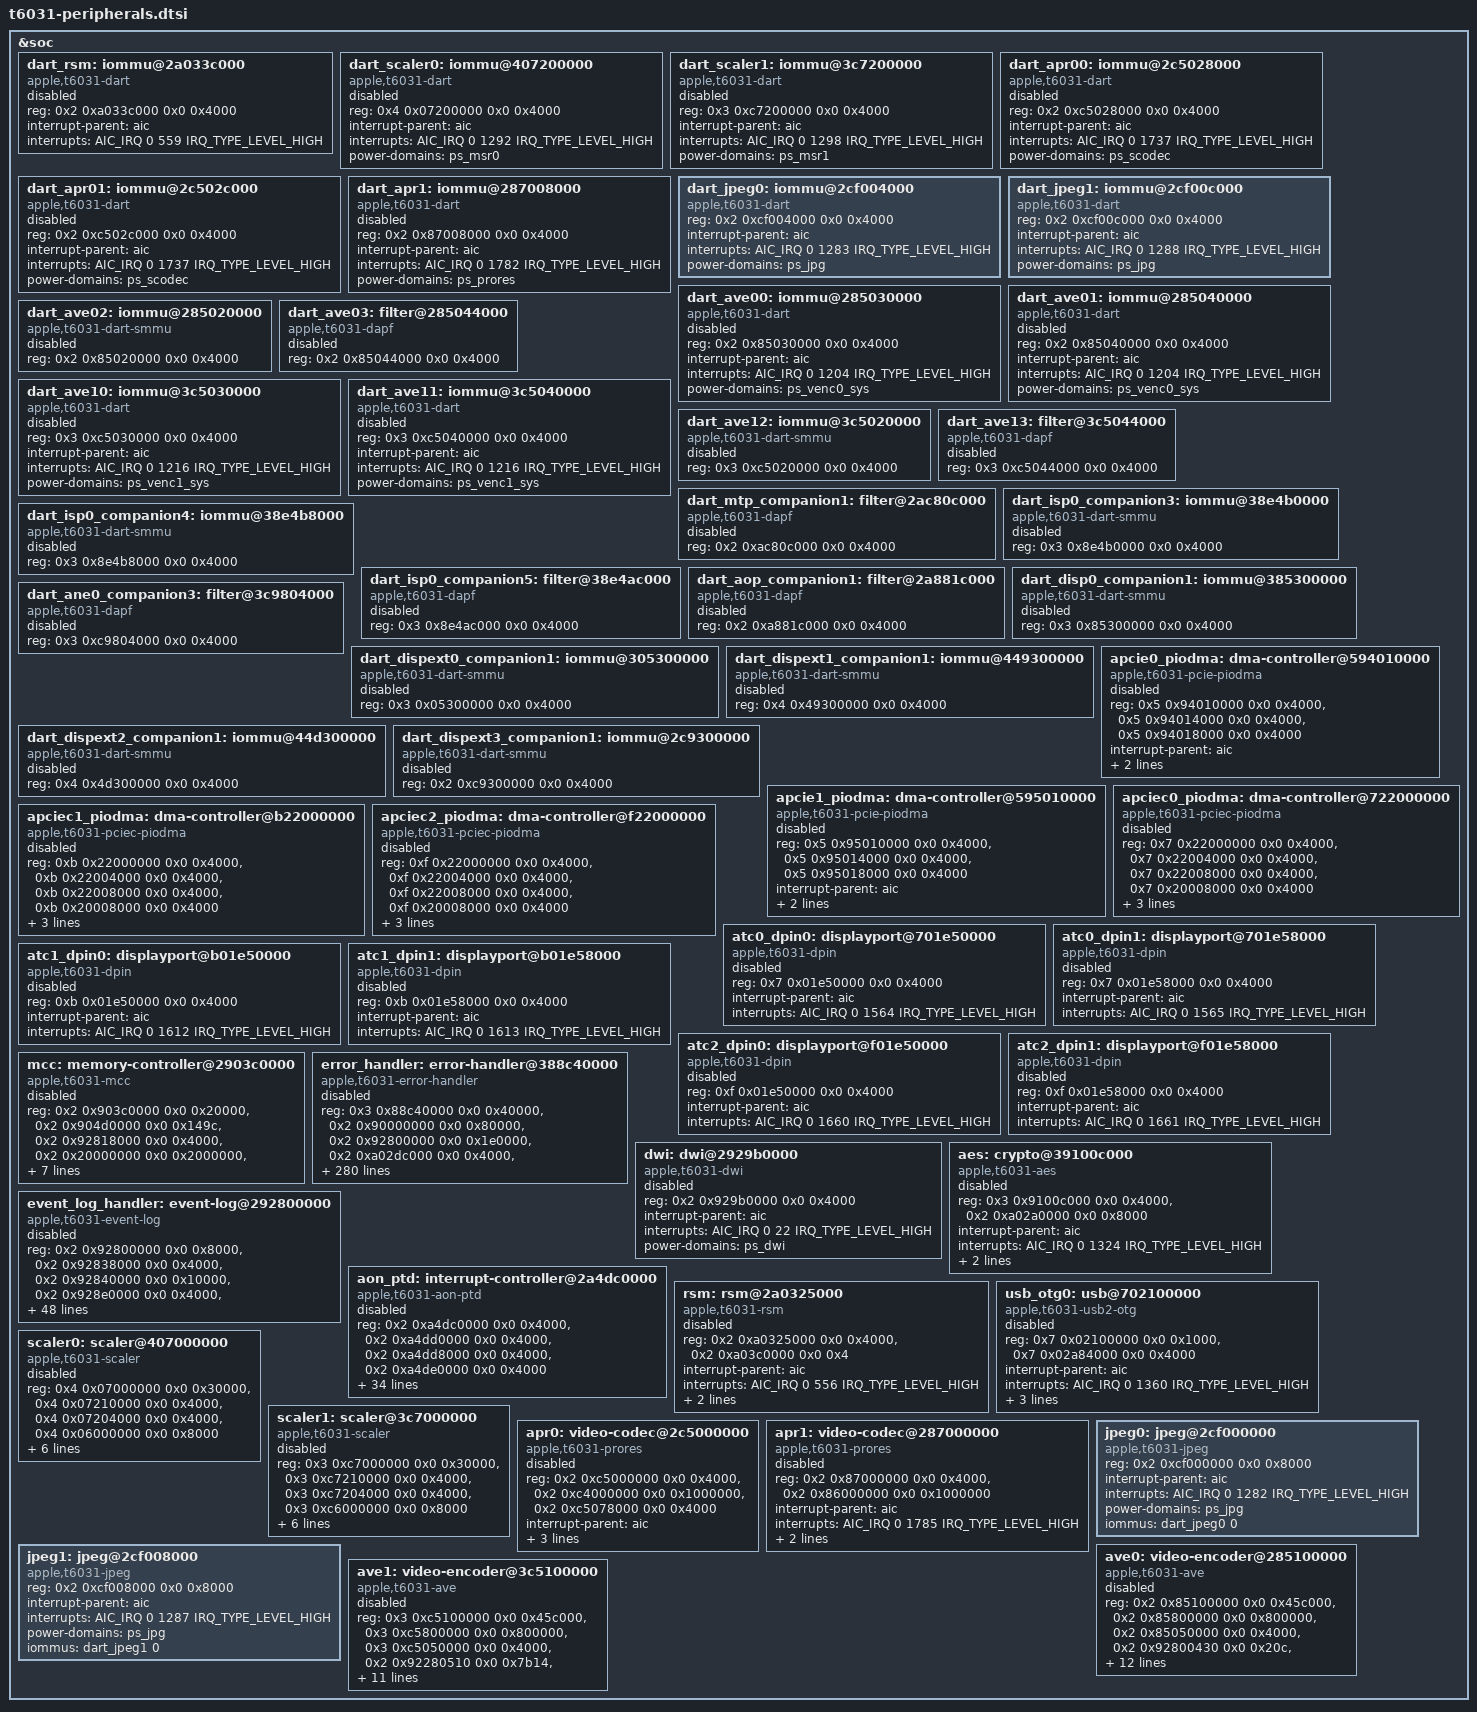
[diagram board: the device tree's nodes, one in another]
// SPDX-License-Identifier: GPL-2.0+ OR MIT
/* Additional T6031 hardware interfaces. Keep unclaimed engines disabled. */

&soc {
	dart_rsm: iommu@2a033c000 {
		compatible = "apple,t6031-dart", "apple,t8110-dart";
		reg = <0x2 0xa033c000 0x0 0x4000>;
		interrupt-parent = <&aic>;
		interrupts = <AIC_IRQ 0 559 IRQ_TYPE_LEVEL_HIGH>;
		#iommu-cells = <1>;
		status = "disabled";
	};

	dart_scaler0: iommu@407200000 {
		compatible = "apple,t6031-dart", "apple,t8110-dart";
		reg = <0x4 0x07200000 0x0 0x4000>;
		interrupt-parent = <&aic>;
		interrupts = <AIC_IRQ 0 1292 IRQ_TYPE_LEVEL_HIGH>;
		#iommu-cells = <1>;
		power-domains = <&ps_msr0>;
		status = "disabled";
	};

	dart_scaler1: iommu@3c7200000 {
		compatible = "apple,t6031-dart", "apple,t8110-dart";
		reg = <0x3 0xc7200000 0x0 0x4000>;
		interrupt-parent = <&aic>;
		interrupts = <AIC_IRQ 0 1298 IRQ_TYPE_LEVEL_HIGH>;
		#iommu-cells = <1>;
		power-domains = <&ps_msr1>;
		status = "disabled";
	};

	dart_apr00: iommu@2c5028000 {
		compatible = "apple,t6031-dart", "apple,t8110-dart";
		reg = <0x2 0xc5028000 0x0 0x4000>;
		interrupt-parent = <&aic>;
		interrupts = <AIC_IRQ 0 1737 IRQ_TYPE_LEVEL_HIGH>;
		#iommu-cells = <1>;
		power-domains = <&ps_scodec>;
		status = "disabled";
	};

	dart_apr01: iommu@2c502c000 {
		compatible = "apple,t6031-dart", "apple,t8110-dart";
		reg = <0x2 0xc502c000 0x0 0x4000>;
		interrupt-parent = <&aic>;
		interrupts = <AIC_IRQ 0 1737 IRQ_TYPE_LEVEL_HIGH>;
		#iommu-cells = <1>;
		power-domains = <&ps_scodec>;
		status = "disabled";
	};

	dart_apr1: iommu@287008000 {
		compatible = "apple,t6031-dart", "apple,t8110-dart";
		reg = <0x2 0x87008000 0x0 0x4000>;
		interrupt-parent = <&aic>;
		interrupts = <AIC_IRQ 0 1782 IRQ_TYPE_LEVEL_HIGH>;
		#iommu-cells = <1>;
		power-domains = <&ps_prores>;
		status = "disabled";
	};

	dart_jpeg0: iommu@2cf004000 {
		compatible = "apple,t6031-dart", "apple,t8110-dart";
		reg = <0x2 0xcf004000 0x0 0x4000>;
		interrupt-parent = <&aic>;
		interrupts = <AIC_IRQ 0 1283 IRQ_TYPE_LEVEL_HIGH>;
		#iommu-cells = <1>;
		power-domains = <&ps_jpg>;
		status = "okay";
	};

	dart_jpeg1: iommu@2cf00c000 {
		compatible = "apple,t6031-dart", "apple,t8110-dart";
		reg = <0x2 0xcf00c000 0x0 0x4000>;
		interrupt-parent = <&aic>;
		interrupts = <AIC_IRQ 0 1288 IRQ_TYPE_LEVEL_HIGH>;
		#iommu-cells = <1>;
		power-domains = <&ps_jpg>;
		status = "okay";
	};

	dart_ave00: iommu@285030000 {
		compatible = "apple,t6031-dart", "apple,t8110-dart";
		reg = <0x2 0x85030000 0x0 0x4000>;
		interrupt-parent = <&aic>;
		interrupts = <AIC_IRQ 0 1204 IRQ_TYPE_LEVEL_HIGH>;
		#iommu-cells = <1>;
		power-domains = <&ps_venc0_sys>;
		status = "disabled";
	};

	dart_ave01: iommu@285040000 {
		compatible = "apple,t6031-dart", "apple,t8110-dart";
		reg = <0x2 0x85040000 0x0 0x4000>;
		interrupt-parent = <&aic>;
		interrupts = <AIC_IRQ 0 1204 IRQ_TYPE_LEVEL_HIGH>;
		#iommu-cells = <1>;
		power-domains = <&ps_venc0_sys>;
		status = "disabled";
	};

	dart_ave02: iommu@285020000 {
		compatible = "apple,t6031-dart-smmu", "apple,dart-smmu";
		reg = <0x2 0x85020000 0x0 0x4000>;
		status = "disabled";
	};

	dart_ave03: filter@285044000 {
		compatible = "apple,t6031-dapf", "apple,dapf";
		reg = <0x2 0x85044000 0x0 0x4000>;
		status = "disabled";
	};

	dart_ave10: iommu@3c5030000 {
		compatible = "apple,t6031-dart", "apple,t8110-dart";
		reg = <0x3 0xc5030000 0x0 0x4000>;
		interrupt-parent = <&aic>;
		interrupts = <AIC_IRQ 0 1216 IRQ_TYPE_LEVEL_HIGH>;
		#iommu-cells = <1>;
		power-domains = <&ps_venc1_sys>;
		status = "disabled";
	};

	dart_ave11: iommu@3c5040000 {
		compatible = "apple,t6031-dart", "apple,t8110-dart";
		reg = <0x3 0xc5040000 0x0 0x4000>;
		interrupt-parent = <&aic>;
		interrupts = <AIC_IRQ 0 1216 IRQ_TYPE_LEVEL_HIGH>;
		#iommu-cells = <1>;
		power-domains = <&ps_venc1_sys>;
		status = "disabled";
	};

	dart_ave12: iommu@3c5020000 {
		compatible = "apple,t6031-dart-smmu", "apple,dart-smmu";
		reg = <0x3 0xc5020000 0x0 0x4000>;
		status = "disabled";
	};

	dart_ave13: filter@3c5044000 {
		compatible = "apple,t6031-dapf", "apple,dapf";
		reg = <0x3 0xc5044000 0x0 0x4000>;
		status = "disabled";
	};

	dart_mtp_companion1: filter@2ac80c000 {
		compatible = "apple,t6031-dapf", "apple,dapf";
		reg = <0x2 0xac80c000 0x0 0x4000>;
		status = "disabled";
	};

	dart_isp0_companion3: iommu@38e4b0000 {
		compatible = "apple,t6031-dart-smmu", "apple,dart-smmu";
		reg = <0x3 0x8e4b0000 0x0 0x4000>;
		status = "disabled";
	};

	dart_isp0_companion4: iommu@38e4b8000 {
		compatible = "apple,t6031-dart-smmu", "apple,dart-smmu";
		reg = <0x3 0x8e4b8000 0x0 0x4000>;
		status = "disabled";
	};

	dart_isp0_companion5: filter@38e4ac000 {
		compatible = "apple,t6031-dapf", "apple,dapf";
		reg = <0x3 0x8e4ac000 0x0 0x4000>;
		status = "disabled";
	};

	dart_aop_companion1: filter@2a881c000 {
		compatible = "apple,t6031-dapf", "apple,dapf";
		reg = <0x2 0xa881c000 0x0 0x4000>;
		status = "disabled";
	};

	dart_disp0_companion1: iommu@385300000 {
		compatible = "apple,t6031-dart-smmu", "apple,dart-smmu";
		reg = <0x3 0x85300000 0x0 0x4000>;
		status = "disabled";
	};

	dart_ane0_companion3: filter@3c9804000 {
		compatible = "apple,t6031-dapf", "apple,dapf";
		reg = <0x3 0xc9804000 0x0 0x4000>;
		status = "disabled";
	};

	dart_dispext0_companion1: iommu@305300000 {
		compatible = "apple,t6031-dart-smmu", "apple,dart-smmu";
		reg = <0x3 0x05300000 0x0 0x4000>;
		status = "disabled";
	};

	dart_dispext1_companion1: iommu@449300000 {
		compatible = "apple,t6031-dart-smmu", "apple,dart-smmu";
		reg = <0x4 0x49300000 0x0 0x4000>;
		status = "disabled";
	};

	dart_dispext2_companion1: iommu@44d300000 {
		compatible = "apple,t6031-dart-smmu", "apple,dart-smmu";
		reg = <0x4 0x4d300000 0x0 0x4000>;
		status = "disabled";
	};

	dart_dispext3_companion1: iommu@2c9300000 {
		compatible = "apple,t6031-dart-smmu", "apple,dart-smmu";
		reg = <0x2 0xc9300000 0x0 0x4000>;
		status = "disabled";
	};

	apcie0_piodma: dma-controller@594010000 {
		compatible = "apple,t6031-pcie-piodma", "apple,pcie-piodma";
		reg = <0x5 0x94010000 0x0 0x4000>,
		      <0x5 0x94014000 0x0 0x4000>,
		      <0x5 0x94018000 0x0 0x4000>;
		interrupt-parent = <&aic>;
		interrupts = <AIC_IRQ 0 1493 IRQ_TYPE_LEVEL_HIGH>;
		iommus = <&pcie0_dart_0 15>;
		status = "disabled";
	};

	apcie1_piodma: dma-controller@595010000 {
		compatible = "apple,t6031-pcie-piodma", "apple,pcie-piodma";
		reg = <0x5 0x95010000 0x0 0x4000>,
		      <0x5 0x95014000 0x0 0x4000>,
		      <0x5 0x95018000 0x0 0x4000>;
		interrupt-parent = <&aic>;
		interrupts = <AIC_IRQ 0 1502 IRQ_TYPE_LEVEL_HIGH>;
		iommus = <&pcie0_dart_1 15>;
		status = "disabled";
	};

	apciec0_piodma: dma-controller@722000000 {
		compatible = "apple,t6031-pciec-piodma", "apple,pciec-piodma";
		reg = <0x7 0x22000000 0x0 0x4000>,
		      <0x7 0x22004000 0x0 0x4000>,
		      <0x7 0x22008000 0x0 0x4000>,
		      <0x7 0x20008000 0x0 0x4000>;
		interrupt-parent = <&aic>;
		interrupts = <AIC_IRQ 0 1349 IRQ_TYPE_LEVEL_HIGH>;
		iommus = <&pciec0_dart 15>;
		status = "disabled";
	};

	apciec1_piodma: dma-controller@b22000000 {
		compatible = "apple,t6031-pciec-piodma", "apple,pciec-piodma";
		reg = <0xb 0x22000000 0x0 0x4000>,
		      <0xb 0x22004000 0x0 0x4000>,
		      <0xb 0x22008000 0x0 0x4000>,
		      <0xb 0x20008000 0x0 0x4000>;
		interrupt-parent = <&aic>;
		interrupts = <AIC_IRQ 0 1377 IRQ_TYPE_LEVEL_HIGH>;
		iommus = <&pciec1_dart 15>;
		status = "disabled";
	};

	apciec2_piodma: dma-controller@f22000000 {
		compatible = "apple,t6031-pciec-piodma", "apple,pciec-piodma";
		reg = <0xf 0x22000000 0x0 0x4000>,
		      <0xf 0x22004000 0x0 0x4000>,
		      <0xf 0x22008000 0x0 0x4000>,
		      <0xf 0x20008000 0x0 0x4000>;
		interrupt-parent = <&aic>;
		interrupts = <AIC_IRQ 0 1405 IRQ_TYPE_LEVEL_HIGH>;
		iommus = <&pciec2_dart 15>;
		status = "disabled";
	};

	atc0_dpin0: displayport@701e50000 {
		compatible = "apple,t6031-dpin", "apple,dpin";
		reg = <0x7 0x01e50000 0x0 0x4000>;
		interrupt-parent = <&aic>;
		interrupts = <AIC_IRQ 0 1564 IRQ_TYPE_LEVEL_HIGH>;
		status = "disabled";
	};

	atc0_dpin1: displayport@701e58000 {
		compatible = "apple,t6031-dpin", "apple,dpin";
		reg = <0x7 0x01e58000 0x0 0x4000>;
		interrupt-parent = <&aic>;
		interrupts = <AIC_IRQ 0 1565 IRQ_TYPE_LEVEL_HIGH>;
		status = "disabled";
	};

	atc1_dpin0: displayport@b01e50000 {
		compatible = "apple,t6031-dpin", "apple,dpin";
		reg = <0xb 0x01e50000 0x0 0x4000>;
		interrupt-parent = <&aic>;
		interrupts = <AIC_IRQ 0 1612 IRQ_TYPE_LEVEL_HIGH>;
		status = "disabled";
	};

	atc1_dpin1: displayport@b01e58000 {
		compatible = "apple,t6031-dpin", "apple,dpin";
		reg = <0xb 0x01e58000 0x0 0x4000>;
		interrupt-parent = <&aic>;
		interrupts = <AIC_IRQ 0 1613 IRQ_TYPE_LEVEL_HIGH>;
		status = "disabled";
	};

	atc2_dpin0: displayport@f01e50000 {
		compatible = "apple,t6031-dpin", "apple,dpin";
		reg = <0xf 0x01e50000 0x0 0x4000>;
		interrupt-parent = <&aic>;
		interrupts = <AIC_IRQ 0 1660 IRQ_TYPE_LEVEL_HIGH>;
		status = "disabled";
	};

	atc2_dpin1: displayport@f01e58000 {
		compatible = "apple,t6031-dpin", "apple,dpin";
		reg = <0xf 0x01e58000 0x0 0x4000>;
		interrupt-parent = <&aic>;
		interrupts = <AIC_IRQ 0 1661 IRQ_TYPE_LEVEL_HIGH>;
		status = "disabled";
	};

	mcc: memory-controller@2903c0000 {
		compatible = "apple,t6031-mcc", "apple,mcc";
		reg = <0x2 0x903c0000 0x0 0x20000>,
		      <0x2 0x904d0000 0x0 0x149c>,
		      <0x2 0x92818000 0x0 0x4000>,
		      <0x2 0x20000000 0x0 0x2000000>,
		      <0x2 0x22000000 0x0 0x2000000>,
		      <0x2 0x24000000 0x0 0x2000000>,
		      <0x2 0x26000000 0x0 0x2000000>,
		      <0x2 0x28000000 0x0 0x2000000>,
		      <0x2 0x2a000000 0x0 0x2000000>,
		      <0x2 0x2c000000 0x0 0x2000000>,
		      <0x2 0x2e000000 0x0 0x2000000>;
		status = "disabled";
	};

	error_handler: error-handler@388c40000 {
		compatible = "apple,t6031-error-handler", "apple,soc-error-handler";
		reg = <0x3 0x88c40000 0x0 0x40000>,
		      <0x2 0x90000000 0x0 0x80000>,
		      <0x2 0x92800000 0x0 0x1e0000>,
		      <0x2 0xa02dc000 0x0 0x4000>,
		      <0x2 0x20000000 0x0 0x2000000>,
		      <0x2 0x22000000 0x0 0x2000000>,
		      <0x2 0x24000000 0x0 0x2000000>,
		      <0x2 0x26000000 0x0 0x2000000>,
		      <0x2 0x28000000 0x0 0x2000000>,
		      <0x2 0x2a000000 0x0 0x2000000>,
		      <0x2 0x2c000000 0x0 0x2000000>,
		      <0x2 0x2e000000 0x0 0x2000000>,
		      <0x2 0x80000000 0x0 0x4000>,
		      <0x3 0x00000000 0x0 0x4000>,
		      <0x3 0x40000000 0x0 0x4000>,
		      <0x3 0x80000000 0x0 0x4000>,
		      <0x2 0xc0000000 0x0 0x4000>,
		      <0x3 0xc0000000 0x0 0x4000>,
		      <0x4 0x00000000 0x0 0x4000>,
		      <0x4 0x40000000 0x0 0x4000>,
		      <0x2 0xa0000000 0x0 0x20000>,
		      <0x2 0x902c0000 0x0 0x18000>,
		      <0x2 0xa4800000 0x0 0x4000>,
		      <0x2 0x59c00000 0x0 0x40000>,
		      <0x2 0x5a000000 0x0 0x40000>,
		      <0x2 0x64400000 0x0 0x40000>,
		      <0x2 0x64000000 0x0 0x40000>,
		      <0x2 0x67000000 0x0 0x40000>,
		      <0x2 0x60400000 0x0 0x40000>,
		      <0x2 0x60800000 0x0 0x40000>,
		      <0x2 0x67400000 0x0 0x40000>,
		      <0x2 0x60c00000 0x0 0x40000>,
		      <0x2 0x61000000 0x0 0x40000>,
		      <0x2 0x61400000 0x0 0x40000>,
		      <0x2 0x4f800000 0x0 0x40000>,
		      <0x2 0x51800000 0x0 0x40000>,
		      <0x2 0x51c00000 0x0 0x40000>,
		      <0x2 0x4fc00000 0x0 0x40000>,
		      <0x2 0x52000000 0x0 0x40000>,
		      <0x4 0x0b180000 0x0 0x18000>,
		      <0x4 0x0b1a0000 0x0 0x18000>,
		      <0x4 0x0b380000 0x0 0x18000>,
		      <0x4 0x0b3a0000 0x0 0x18000>,
		      <0x4 0x0b000000 0x0 0x18000>,
		      <0x4 0x0b200000 0x0 0x18000>,
		      <0x4 0x0b080000 0x0 0x18000>,
		      <0x4 0x0b280000 0x0 0x18000>,
		      <0x4 0x0b600000 0x0 0x18000>,
		      <0x4 0x0b400000 0x0 0x18000>,
		      <0x4 0x0b680000 0x0 0x18000>,
		      <0x4 0x0b480000 0x0 0x18000>,
		      <0x4 0x0b040000 0x0 0x18000>,
		      <0x4 0x0b240000 0x0 0x18000>,
		      <0x4 0x0b0c0000 0x0 0x18000>,
		      <0x4 0x0b2c0000 0x0 0x18000>,
		      <0x4 0x0b640000 0x0 0x18000>,
		      <0x4 0x0b440000 0x0 0x18000>,
		      <0x4 0x0b6c0000 0x0 0x18000>,
		      <0x4 0x0b4c0000 0x0 0x18000>,
		      <0x2 0x59400000 0x0 0x40000>,
		      <0x2 0x5fc00000 0x0 0x40000>,
		      <0x2 0x63800000 0x0 0x40000>,
		      <0x2 0x66800000 0x0 0x40000>,
		      <0x2 0x59800000 0x0 0x40000>,
		      <0x2 0x60000000 0x0 0x40000>,
		      <0x2 0x63c00000 0x0 0x40000>,
		      <0x2 0x66c00000 0x0 0x40000>,
		      <0x2 0x4f400000 0x0 0x40000>,
		      <0x2 0x51400000 0x0 0x40000>,
		      <0x2 0x53c00000 0x0 0x40000>,
		      <0x2 0x56000000 0x0 0x40000>,
		      <0x2 0x54000000 0x0 0x40000>,
		      <0x2 0x56400000 0x0 0x40000>,
		      <0x2 0x54400000 0x0 0x40000>,
		      <0x2 0x56800000 0x0 0x40000>,
		      <0x2 0x53432000 0x0 0x1000>,
		      <0x2 0x4f032000 0x0 0x1000>,
		      <0x2 0x51032000 0x0 0x1000>,
		      <0x2 0x55032000 0x0 0x1000>,
		      <0x2 0x53032000 0x0 0x1000>,
		      <0x2 0x55432000 0x0 0x1000>,
		      <0x2 0x5e832000 0x0 0x1000>,
		      <0x2 0x62832000 0x0 0x1000>,
		      <0x2 0x65832000 0x0 0x1000>,
		      <0x2 0x58432000 0x0 0x1000>,
		      <0x2 0x5ec32000 0x0 0x1000>,
		      <0x2 0x62c32000 0x0 0x1000>,
		      <0x2 0x58032000 0x0 0x1000>,
		      <0x2 0x63032000 0x0 0x1000>,
		      <0x2 0x65c32000 0x0 0x1000>,
		      <0x2 0x58832000 0x0 0x1000>,
		      <0x2 0x58c32000 0x0 0x1000>,
		      <0x2 0x63432000 0x0 0x1000>,
		      <0x2 0x5f032000 0x0 0x1000>,
		      <0x2 0x66032000 0x0 0x1000>,
		      <0x2 0x5f432000 0x0 0x1000>,
		      <0x2 0x66432000 0x0 0x1000>,
		      <0x4 0x0b114000 0x0 0x1f000>,
		      <0x4 0x0b314000 0x0 0x1f000>,
		      <0x4 0x0b134000 0x0 0x1f000>,
		      <0x4 0x0b334000 0x0 0x1f000>,
		      <0x4 0x0b714000 0x0 0x1f000>,
		      <0x4 0x0b514000 0x0 0x1f000>,
		      <0x4 0x0b734000 0x0 0x1f000>,
		      <0x4 0x0b534000 0x0 0x1f000>,
		      <0x4 0x0b030000 0x0 0x4000>,
		      <0x4 0x0b230000 0x0 0x4000>,
		      <0x4 0x0b030000 0x0 0x4000>,
		      <0x4 0x0b230000 0x0 0x4000>,
		      <0x4 0x0b630000 0x0 0x4000>,
		      <0x4 0x0b430000 0x0 0x4000>,
		      <0x4 0x0b030000 0x0 0x4000>,
		      <0x4 0x0b230000 0x0 0x4000>,
		      <0x4 0x0b030000 0x0 0x4000>,
		      <0x4 0x0b230000 0x0 0x4000>,
		      <0x4 0x0b630000 0x0 0x4000>,
		      <0x4 0x0b430000 0x0 0x4000>,
		      <0x4 0x0b630000 0x0 0x4000>,
		      <0x4 0x0b430000 0x0 0x4000>,
		      <0x4 0x0b630000 0x0 0x4000>,
		      <0x4 0x0b430000 0x0 0x4000>,
		      <0x4 0x0b1e0000 0x0 0x4000>,
		      <0x4 0x0b3e0000 0x0 0x4000>;
		interrupt-parent = <&aic>;
		interrupts = <AIC_IRQ 0 578 IRQ_TYPE_LEVEL_HIGH>,
		             <AIC_IRQ 0 577 IRQ_TYPE_LEVEL_HIGH>,
		             <AIC_IRQ 0 584 IRQ_TYPE_LEVEL_HIGH>,
		             <AIC_IRQ 0 583 IRQ_TYPE_LEVEL_HIGH>,
		             <AIC_IRQ 0 580 IRQ_TYPE_LEVEL_HIGH>,
		             <AIC_IRQ 0 581 IRQ_TYPE_LEVEL_HIGH>,
		             <AIC_IRQ 0 585 IRQ_TYPE_LEVEL_HIGH>,
		             <AIC_IRQ 0 582 IRQ_TYPE_LEVEL_HIGH>,
		             <AIC_IRQ 0 476 IRQ_TYPE_LEVEL_HIGH>,
		             <AIC_IRQ 0 486 IRQ_TYPE_LEVEL_HIGH>,
		             <AIC_IRQ 0 496 IRQ_TYPE_LEVEL_HIGH>,
		             <AIC_IRQ 0 506 IRQ_TYPE_LEVEL_HIGH>,
		             <AIC_IRQ 0 516 IRQ_TYPE_LEVEL_HIGH>,
		             <AIC_IRQ 0 526 IRQ_TYPE_LEVEL_HIGH>,
		             <AIC_IRQ 0 536 IRQ_TYPE_LEVEL_HIGH>,
		             <AIC_IRQ 0 546 IRQ_TYPE_LEVEL_HIGH>,
		             <AIC_IRQ 0 335 IRQ_TYPE_LEVEL_HIGH>,
		             <AIC_IRQ 0 339 IRQ_TYPE_LEVEL_HIGH>,
		             <AIC_IRQ 0 341 IRQ_TYPE_LEVEL_HIGH>,
		             <AIC_IRQ 0 343 IRQ_TYPE_LEVEL_HIGH>,
		             <AIC_IRQ 0 337 IRQ_TYPE_LEVEL_HIGH>,
		             <AIC_IRQ 0 345 IRQ_TYPE_LEVEL_HIGH>,
		             <AIC_IRQ 0 347 IRQ_TYPE_LEVEL_HIGH>,
		             <AIC_IRQ 0 349 IRQ_TYPE_LEVEL_HIGH>,
		             <AIC_IRQ 0 919 IRQ_TYPE_LEVEL_HIGH>,
		             <AIC_IRQ 0 421 IRQ_TYPE_LEVEL_HIGH>,
		             <AIC_IRQ 0 779 IRQ_TYPE_LEVEL_HIGH>,
		             <AIC_IRQ 0 480 IRQ_TYPE_LEVEL_HIGH>,
		             <AIC_IRQ 0 481 IRQ_TYPE_LEVEL_HIGH>,
		             <AIC_IRQ 0 482 IRQ_TYPE_LEVEL_HIGH>,
		             <AIC_IRQ 0 483 IRQ_TYPE_LEVEL_HIGH>,
		             <AIC_IRQ 0 490 IRQ_TYPE_LEVEL_HIGH>,
		             <AIC_IRQ 0 491 IRQ_TYPE_LEVEL_HIGH>,
		             <AIC_IRQ 0 492 IRQ_TYPE_LEVEL_HIGH>,
		             <AIC_IRQ 0 493 IRQ_TYPE_LEVEL_HIGH>,
		             <AIC_IRQ 0 500 IRQ_TYPE_LEVEL_HIGH>,
		             <AIC_IRQ 0 501 IRQ_TYPE_LEVEL_HIGH>,
		             <AIC_IRQ 0 502 IRQ_TYPE_LEVEL_HIGH>,
		             <AIC_IRQ 0 503 IRQ_TYPE_LEVEL_HIGH>,
		             <AIC_IRQ 0 510 IRQ_TYPE_LEVEL_HIGH>,
		             <AIC_IRQ 0 511 IRQ_TYPE_LEVEL_HIGH>,
		             <AIC_IRQ 0 512 IRQ_TYPE_LEVEL_HIGH>,
		             <AIC_IRQ 0 513 IRQ_TYPE_LEVEL_HIGH>,
		             <AIC_IRQ 0 520 IRQ_TYPE_LEVEL_HIGH>,
		             <AIC_IRQ 0 521 IRQ_TYPE_LEVEL_HIGH>,
		             <AIC_IRQ 0 522 IRQ_TYPE_LEVEL_HIGH>,
		             <AIC_IRQ 0 523 IRQ_TYPE_LEVEL_HIGH>,
		             <AIC_IRQ 0 530 IRQ_TYPE_LEVEL_HIGH>,
		             <AIC_IRQ 0 531 IRQ_TYPE_LEVEL_HIGH>,
		             <AIC_IRQ 0 532 IRQ_TYPE_LEVEL_HIGH>,
		             <AIC_IRQ 0 533 IRQ_TYPE_LEVEL_HIGH>,
		             <AIC_IRQ 0 540 IRQ_TYPE_LEVEL_HIGH>,
		             <AIC_IRQ 0 541 IRQ_TYPE_LEVEL_HIGH>,
		             <AIC_IRQ 0 542 IRQ_TYPE_LEVEL_HIGH>,
		             <AIC_IRQ 0 543 IRQ_TYPE_LEVEL_HIGH>,
		             <AIC_IRQ 0 550 IRQ_TYPE_LEVEL_HIGH>,
		             <AIC_IRQ 0 551 IRQ_TYPE_LEVEL_HIGH>,
		             <AIC_IRQ 0 552 IRQ_TYPE_LEVEL_HIGH>,
		             <AIC_IRQ 0 553 IRQ_TYPE_LEVEL_HIGH>,
		             <AIC_IRQ 0 289 IRQ_TYPE_LEVEL_HIGH>,
		             <AIC_IRQ 0 290 IRQ_TYPE_LEVEL_HIGH>,
		             <AIC_IRQ 0 296 IRQ_TYPE_LEVEL_HIGH>,
		             <AIC_IRQ 0 291 IRQ_TYPE_LEVEL_HIGH>,
		             <AIC_IRQ 0 292 IRQ_TYPE_LEVEL_HIGH>,
		             <AIC_IRQ 0 293 IRQ_TYPE_LEVEL_HIGH>,
		             <AIC_IRQ 0 294 IRQ_TYPE_LEVEL_HIGH>,
		             <AIC_IRQ 0 295 IRQ_TYPE_LEVEL_HIGH>,
		             <AIC_IRQ 0 278 IRQ_TYPE_LEVEL_HIGH>,
		             <AIC_IRQ 0 279 IRQ_TYPE_LEVEL_HIGH>,
		             <AIC_IRQ 0 280 IRQ_TYPE_LEVEL_HIGH>,
		             <AIC_IRQ 0 260 IRQ_TYPE_LEVEL_HIGH>,
		             <AIC_IRQ 0 261 IRQ_TYPE_LEVEL_HIGH>,
		             <AIC_IRQ 0 263 IRQ_TYPE_LEVEL_HIGH>,
		             <AIC_IRQ 0 264 IRQ_TYPE_LEVEL_HIGH>,
		             <AIC_IRQ 0 262 IRQ_TYPE_LEVEL_HIGH>,
		             <AIC_IRQ 0 215 IRQ_TYPE_LEVEL_HIGH>,
		             <AIC_IRQ 0 214 IRQ_TYPE_LEVEL_HIGH>,
		             <AIC_IRQ 0 217 IRQ_TYPE_LEVEL_HIGH>,
		             <AIC_IRQ 0 216 IRQ_TYPE_LEVEL_HIGH>,
		             <AIC_IRQ 0 218 IRQ_TYPE_LEVEL_HIGH>,
		             <AIC_IRQ 0 219 IRQ_TYPE_LEVEL_HIGH>,
		             <AIC_IRQ 0 220 IRQ_TYPE_LEVEL_HIGH>,
		             <AIC_IRQ 0 221 IRQ_TYPE_LEVEL_HIGH>,
		             <AIC_IRQ 0 222 IRQ_TYPE_LEVEL_HIGH>,
		             <AIC_IRQ 0 223 IRQ_TYPE_LEVEL_HIGH>,
		             <AIC_IRQ 0 224 IRQ_TYPE_LEVEL_HIGH>,
		             <AIC_IRQ 0 225 IRQ_TYPE_LEVEL_HIGH>,
		             <AIC_IRQ 0 226 IRQ_TYPE_LEVEL_HIGH>,
		             <AIC_IRQ 0 227 IRQ_TYPE_LEVEL_HIGH>,
		             <AIC_IRQ 0 228 IRQ_TYPE_LEVEL_HIGH>,
		             <AIC_IRQ 0 229 IRQ_TYPE_LEVEL_HIGH>,
		             <AIC_IRQ 0 230 IRQ_TYPE_LEVEL_HIGH>,
		             <AIC_IRQ 0 231 IRQ_TYPE_LEVEL_HIGH>,
		             <AIC_IRQ 0 232 IRQ_TYPE_LEVEL_HIGH>,
		             <AIC_IRQ 0 233 IRQ_TYPE_LEVEL_HIGH>,
		             <AIC_IRQ 0 281 IRQ_TYPE_LEVEL_HIGH>,
		             <AIC_IRQ 0 282 IRQ_TYPE_LEVEL_HIGH>,
		             <AIC_IRQ 0 283 IRQ_TYPE_LEVEL_HIGH>,
		             <AIC_IRQ 0 284 IRQ_TYPE_LEVEL_HIGH>,
		             <AIC_IRQ 0 285 IRQ_TYPE_LEVEL_HIGH>,
		             <AIC_IRQ 0 286 IRQ_TYPE_LEVEL_HIGH>,
		             <AIC_IRQ 0 287 IRQ_TYPE_LEVEL_HIGH>,
		             <AIC_IRQ 0 288 IRQ_TYPE_LEVEL_HIGH>,
		             <AIC_IRQ 0 265 IRQ_TYPE_LEVEL_HIGH>,
		             <AIC_IRQ 0 266 IRQ_TYPE_LEVEL_HIGH>,
		             <AIC_IRQ 0 267 IRQ_TYPE_LEVEL_HIGH>,
		             <AIC_IRQ 0 268 IRQ_TYPE_LEVEL_HIGH>,
		             <AIC_IRQ 0 269 IRQ_TYPE_LEVEL_HIGH>,
		             <AIC_IRQ 0 270 IRQ_TYPE_LEVEL_HIGH>,
		             <AIC_IRQ 0 271 IRQ_TYPE_LEVEL_HIGH>,
		             <AIC_IRQ 0 272 IRQ_TYPE_LEVEL_HIGH>,
		             <AIC_IRQ 0 190 IRQ_TYPE_LEVEL_HIGH>,
		             <AIC_IRQ 0 191 IRQ_TYPE_LEVEL_HIGH>,
		             <AIC_IRQ 0 192 IRQ_TYPE_LEVEL_HIGH>,
		             <AIC_IRQ 0 193 IRQ_TYPE_LEVEL_HIGH>,
		             <AIC_IRQ 0 189 IRQ_TYPE_LEVEL_HIGH>,
		             <AIC_IRQ 0 194 IRQ_TYPE_LEVEL_HIGH>,
		             <AIC_IRQ 0 196 IRQ_TYPE_LEVEL_HIGH>,
		             <AIC_IRQ 0 197 IRQ_TYPE_LEVEL_HIGH>,
		             <AIC_IRQ 0 198 IRQ_TYPE_LEVEL_HIGH>,
		             <AIC_IRQ 0 199 IRQ_TYPE_LEVEL_HIGH>,
		             <AIC_IRQ 0 200 IRQ_TYPE_LEVEL_HIGH>,
		             <AIC_IRQ 0 201 IRQ_TYPE_LEVEL_HIGH>,
		             <AIC_IRQ 0 195 IRQ_TYPE_LEVEL_HIGH>,
		             <AIC_IRQ 0 204 IRQ_TYPE_LEVEL_HIGH>,
		             <AIC_IRQ 0 202 IRQ_TYPE_LEVEL_HIGH>,
		             <AIC_IRQ 0 203 IRQ_TYPE_LEVEL_HIGH>,
		             <AIC_IRQ 0 205 IRQ_TYPE_LEVEL_HIGH>,
		             <AIC_IRQ 0 206 IRQ_TYPE_LEVEL_HIGH>,
		             <AIC_IRQ 0 207 IRQ_TYPE_LEVEL_HIGH>,
		             <AIC_IRQ 0 208 IRQ_TYPE_LEVEL_HIGH>,
		             <AIC_IRQ 0 209 IRQ_TYPE_LEVEL_HIGH>,
		             <AIC_IRQ 0 210 IRQ_TYPE_LEVEL_HIGH>,
		             <AIC_IRQ 0 179 IRQ_TYPE_LEVEL_HIGH>,
		             <AIC_IRQ 0 180 IRQ_TYPE_LEVEL_HIGH>,
		             <AIC_IRQ 0 181 IRQ_TYPE_LEVEL_HIGH>,
		             <AIC_IRQ 0 182 IRQ_TYPE_LEVEL_HIGH>,
		             <AIC_IRQ 0 183 IRQ_TYPE_LEVEL_HIGH>,
		             <AIC_IRQ 0 184 IRQ_TYPE_LEVEL_HIGH>,
		             <AIC_IRQ 0 185 IRQ_TYPE_LEVEL_HIGH>,
		             <AIC_IRQ 0 186 IRQ_TYPE_LEVEL_HIGH>,
		             <AIC_IRQ 0 236 IRQ_TYPE_LEVEL_HIGH>,
		             <AIC_IRQ 0 237 IRQ_TYPE_LEVEL_HIGH>,
		             <AIC_IRQ 0 238 IRQ_TYPE_LEVEL_HIGH>,
		             <AIC_IRQ 0 239 IRQ_TYPE_LEVEL_HIGH>,
		             <AIC_IRQ 0 240 IRQ_TYPE_LEVEL_HIGH>,
		             <AIC_IRQ 0 241 IRQ_TYPE_LEVEL_HIGH>,
		             <AIC_IRQ 0 244 IRQ_TYPE_LEVEL_HIGH>,
		             <AIC_IRQ 0 245 IRQ_TYPE_LEVEL_HIGH>,
		             <AIC_IRQ 0 246 IRQ_TYPE_LEVEL_HIGH>,
		             <AIC_IRQ 0 247 IRQ_TYPE_LEVEL_HIGH>,
		             <AIC_IRQ 0 248 IRQ_TYPE_LEVEL_HIGH>,
		             <AIC_IRQ 0 249 IRQ_TYPE_LEVEL_HIGH>,
		             <AIC_IRQ 0 242 IRQ_TYPE_LEVEL_HIGH>,
		             <AIC_IRQ 0 243 IRQ_TYPE_LEVEL_HIGH>,
		             <AIC_IRQ 0 250 IRQ_TYPE_LEVEL_HIGH>,
		             <AIC_IRQ 0 251 IRQ_TYPE_LEVEL_HIGH>,
		             <AIC_IRQ 0 234 IRQ_TYPE_LEVEL_HIGH>,
		             <AIC_IRQ 0 235 IRQ_TYPE_LEVEL_HIGH>;
		power-domains = <&ps_gfx>;
		status = "disabled";
	};

	dwi: dwi@2929b0000 {
		compatible = "apple,t6031-dwi", "apple,dwi";
		reg = <0x2 0x929b0000 0x0 0x4000>;
		interrupt-parent = <&aic>;
		interrupts = <AIC_IRQ 0 22 IRQ_TYPE_LEVEL_HIGH>;
		power-domains = <&ps_dwi>;
		status = "disabled";
	};

	aes: crypto@39100c000 {
		compatible = "apple,t6031-aes", "apple,aes";
		reg = <0x3 0x9100c000 0x0 0x4000>,
		      <0x2 0xa02a0000 0x0 0x8000>;
		interrupt-parent = <&aic>;
		interrupts = <AIC_IRQ 0 1324 IRQ_TYPE_LEVEL_HIGH>;
		power-domains = <&ps_aes>;
		iommus = <&sio_dart 1>;
		status = "disabled";
	};

	event_log_handler: event-log@292800000 {
		compatible = "apple,t6031-event-log", "apple,soc-event-log";
		reg = <0x2 0x92800000 0x0 0x8000>,
		      <0x2 0x92838000 0x0 0x4000>,
		      <0x2 0x92840000 0x0 0x10000>,
		      <0x2 0x928e0000 0x0 0x4000>,
		      <0x2 0x92850000 0x0 0x4000>,
		      <0x2 0x92880000 0x0 0x1c000>,
		      <0x2 0x92980000 0x0 0x18000>,
		      <0x2 0x929a0000 0x0 0x4000>,
		      <0x2 0x928c0000 0x0 0x4000>,
		      <0x2 0x92960000 0x0 0x1c000>,
		      <0x2 0x929c0000 0x0 0xc000>,
		      <0x2 0x92280000 0x0 0x10000>,
		      <0x2 0x92294000 0x0 0x4000>,
		      <0x2 0x922b8000 0x0 0x8000>,
		      <0x2 0x922ac000 0x0 0x4000>,
		      <0x2 0x90000000 0x0 0x80000>,
		      <0x2 0xa0280000 0x0 0x10000>,
		      <0x2 0xa029c000 0x0 0x4000>,
		      <0x2 0xa02c0000 0x0 0x10000>,
		      <0x2 0xa02d0000 0x0 0x4000>,
		      <0x2 0xa02d4000 0x0 0x4000>,
		      <0x2 0xa02d8000 0x0 0x4000>,
		      <0x2 0xa02e4000 0x0 0x4000>,
		      <0x2 0xa0200000 0x0 0x80000>,
		      <0x2 0x9020c000 0x0 0x4000>;
		interrupt-parent = <&aic>;
		interrupts = <AIC_IRQ 0 50 IRQ_TYPE_LEVEL_HIGH>,
		             <AIC_IRQ 0 51 IRQ_TYPE_LEVEL_HIGH>,
		             <AIC_IRQ 0 52 IRQ_TYPE_LEVEL_HIGH>,
		             <AIC_IRQ 0 53 IRQ_TYPE_LEVEL_HIGH>,
		             <AIC_IRQ 0 54 IRQ_TYPE_LEVEL_HIGH>,
		             <AIC_IRQ 0 55 IRQ_TYPE_LEVEL_HIGH>,
		             <AIC_IRQ 0 56 IRQ_TYPE_LEVEL_HIGH>,
		             <AIC_IRQ 0 422 IRQ_TYPE_LEVEL_HIGH>,
		             <AIC_IRQ 0 451 IRQ_TYPE_LEVEL_HIGH>,
		             <AIC_IRQ 0 454 IRQ_TYPE_LEVEL_HIGH>,
		             <AIC_IRQ 0 455 IRQ_TYPE_LEVEL_HIGH>,
		             <AIC_IRQ 0 456 IRQ_TYPE_LEVEL_HIGH>,
		             <AIC_IRQ 0 472 IRQ_TYPE_LEVEL_HIGH>,
		             <AIC_IRQ 0 474 IRQ_TYPE_LEVEL_HIGH>,
		             <AIC_IRQ 0 475 IRQ_TYPE_LEVEL_HIGH>,
		             <AIC_IRQ 0 780 IRQ_TYPE_LEVEL_HIGH>,
		             <AIC_IRQ 0 969 IRQ_TYPE_LEVEL_HIGH>,
		             <AIC_IRQ 0 978 IRQ_TYPE_LEVEL_HIGH>,
		             <AIC_IRQ 0 1251 IRQ_TYPE_LEVEL_HIGH>,
		             <AIC_IRQ 0 1253 IRQ_TYPE_LEVEL_HIGH>,
		             <AIC_IRQ 0 1255 IRQ_TYPE_LEVEL_HIGH>,
		             <AIC_IRQ 0 1257 IRQ_TYPE_LEVEL_HIGH>,
		             <AIC_IRQ 0 1259 IRQ_TYPE_LEVEL_HIGH>,
		             <AIC_IRQ 0 1261 IRQ_TYPE_LEVEL_HIGH>,
		             <AIC_IRQ 0 1264 IRQ_TYPE_LEVEL_HIGH>,
		             <AIC_IRQ 0 1268 IRQ_TYPE_LEVEL_HIGH>;
		status = "disabled";
	};

	aon_ptd: interrupt-controller@2a4dc0000 {
		compatible = "apple,t6031-aon-ptd", "apple,aon-ptd";
		reg = <0x2 0xa4dc0000 0x0 0x4000>,
		      <0x2 0xa4dd0000 0x0 0x4000>,
		      <0x2 0xa4dd8000 0x0 0x4000>,
		      <0x2 0xa4de0000 0x0 0x4000>;
		interrupt-parent = <&aic>;
		interrupts = <AIC_IRQ 0 920 IRQ_TYPE_LEVEL_HIGH>,
		             <AIC_IRQ 0 921 IRQ_TYPE_LEVEL_HIGH>,
		             <AIC_IRQ 0 922 IRQ_TYPE_LEVEL_HIGH>,
		             <AIC_IRQ 0 923 IRQ_TYPE_LEVEL_HIGH>,
		             <AIC_IRQ 0 924 IRQ_TYPE_LEVEL_HIGH>,
		             <AIC_IRQ 0 925 IRQ_TYPE_LEVEL_HIGH>,
		             <AIC_IRQ 0 926 IRQ_TYPE_LEVEL_HIGH>,
		             <AIC_IRQ 0 927 IRQ_TYPE_LEVEL_HIGH>,
		             <AIC_IRQ 0 928 IRQ_TYPE_LEVEL_HIGH>,
		             <AIC_IRQ 0 929 IRQ_TYPE_LEVEL_HIGH>,
		             <AIC_IRQ 0 930 IRQ_TYPE_LEVEL_HIGH>,
		             <AIC_IRQ 0 931 IRQ_TYPE_LEVEL_HIGH>,
		             <AIC_IRQ 0 932 IRQ_TYPE_LEVEL_HIGH>,
		             <AIC_IRQ 0 933 IRQ_TYPE_LEVEL_HIGH>,
		             <AIC_IRQ 0 934 IRQ_TYPE_LEVEL_HIGH>,
		             <AIC_IRQ 0 935 IRQ_TYPE_LEVEL_HIGH>,
		             <AIC_IRQ 0 936 IRQ_TYPE_LEVEL_HIGH>,
		             <AIC_IRQ 0 937 IRQ_TYPE_LEVEL_HIGH>,
		             <AIC_IRQ 0 938 IRQ_TYPE_LEVEL_HIGH>,
		             <AIC_IRQ 0 939 IRQ_TYPE_LEVEL_HIGH>,
		             <AIC_IRQ 0 940 IRQ_TYPE_LEVEL_HIGH>,
		             <AIC_IRQ 0 941 IRQ_TYPE_LEVEL_HIGH>,
		             <AIC_IRQ 0 942 IRQ_TYPE_LEVEL_HIGH>,
		             <AIC_IRQ 0 943 IRQ_TYPE_LEVEL_HIGH>,
		             <AIC_IRQ 0 944 IRQ_TYPE_LEVEL_HIGH>,
		             <AIC_IRQ 0 945 IRQ_TYPE_LEVEL_HIGH>,
		             <AIC_IRQ 0 946 IRQ_TYPE_LEVEL_HIGH>,
		             <AIC_IRQ 0 947 IRQ_TYPE_LEVEL_HIGH>,
		             <AIC_IRQ 0 948 IRQ_TYPE_LEVEL_HIGH>,
		             <AIC_IRQ 0 949 IRQ_TYPE_LEVEL_HIGH>,
		             <AIC_IRQ 0 950 IRQ_TYPE_LEVEL_HIGH>,
		             <AIC_IRQ 0 951 IRQ_TYPE_LEVEL_HIGH>;
		interrupt-controller;
		#interrupt-cells = <1>;
		#address-cells = <0>;
		status = "disabled";
	};

	rsm: rsm@2a0325000 {
		compatible = "apple,t6031-rsm", "apple,rsm";
		reg = <0x2 0xa0325000 0x0 0x4000>,
		      <0x2 0xa03c0000 0x0 0x4>;
		interrupt-parent = <&aic>;
		interrupts = <AIC_IRQ 0 556 IRQ_TYPE_LEVEL_HIGH>;
		power-domains = <&ps_debug_gated>;
		iommus = <&dart_rsm 0>;
		status = "disabled";
	};

	usb_otg0: usb@702100000 {
		compatible = "apple,t6031-usb2-otg", "apple,usb2-otg";
		reg = <0x7 0x02100000 0x0 0x1000>,
		      <0x7 0x02a84000 0x0 0x4000>;
		interrupt-parent = <&aic>;
		interrupts = <AIC_IRQ 0 1360 IRQ_TYPE_LEVEL_HIGH>;
		power-domains = <&ps_atc0_usb>;
		iommus = <&dwc3_0_dart_0 1>, <&dwc3_0_dart_1 1>;
		phys = <&atcphy0 PHY_TYPE_USB2>;
		phy-names = "usb2-phy";
		status = "disabled";
	};

	scaler0: scaler@407000000 {
		compatible = "apple,t6031-scaler", "apple,scaler";
		reg = <0x4 0x07000000 0x0 0x30000>,
		      <0x4 0x07210000 0x0 0x4000>,
		      <0x4 0x07204000 0x0 0x4000>,
		      <0x4 0x06000000 0x0 0x8000>;
		interrupt-parent = <&aic>;
		interrupts = <AIC_IRQ 0 1291 IRQ_TYPE_LEVEL_HIGH>,
		             <AIC_IRQ 0 1293 IRQ_TYPE_LEVEL_HIGH>;
		power-domains = <&ps_msr0>, <&ps_msr0_ase_core>;
		iommus = <&dart_scaler0 0>, <&dart_scaler0 1>;
		status = "disabled";
	};

	scaler1: scaler@3c7000000 {
		compatible = "apple,t6031-scaler", "apple,scaler";
		reg = <0x3 0xc7000000 0x0 0x30000>,
		      <0x3 0xc7210000 0x0 0x4000>,
		      <0x3 0xc7204000 0x0 0x4000>,
		      <0x3 0xc6000000 0x0 0x8000>;
		interrupt-parent = <&aic>;
		interrupts = <AIC_IRQ 0 1297 IRQ_TYPE_LEVEL_HIGH>,
		             <AIC_IRQ 0 1299 IRQ_TYPE_LEVEL_HIGH>;
		power-domains = <&ps_msr1>, <&ps_msr1_ase_core>;
		iommus = <&dart_scaler1 0>, <&dart_scaler1 1>;
		status = "disabled";
	};

	apr0: video-codec@2c5000000 {
		compatible = "apple,t6031-prores", "apple,prores";
		reg = <0x2 0xc5000000 0x0 0x4000>,
		      <0x2 0xc4000000 0x0 0x1000000>,
		      <0x2 0xc5078000 0x0 0x4000>;
		interrupt-parent = <&aic>;
		interrupts = <AIC_IRQ 0 1738 IRQ_TYPE_LEVEL_HIGH>;
		power-domains = <&ps_scodec>;
		iommus = <&dart_apr00 1>, <&dart_apr01 1>;
		status = "disabled";
	};

	apr1: video-codec@287000000 {
		compatible = "apple,t6031-prores", "apple,prores";
		reg = <0x2 0x87000000 0x0 0x4000>,
		      <0x2 0x86000000 0x0 0x1000000>;
		interrupt-parent = <&aic>;
		interrupts = <AIC_IRQ 0 1785 IRQ_TYPE_LEVEL_HIGH>;
		power-domains = <&ps_prores>;
		iommus = <&dart_apr1 0>;
		status = "disabled";
	};

	jpeg0: jpeg@2cf000000 {
		compatible = "apple,t6031-jpeg", "apple,jpeg";
		reg = <0x2 0xcf000000 0x0 0x8000>;
		interrupt-parent = <&aic>;
		interrupts = <AIC_IRQ 0 1282 IRQ_TYPE_LEVEL_HIGH>;
		power-domains = <&ps_jpg>;
		iommus = <&dart_jpeg0 0>;
		status = "okay";
	};

	jpeg1: jpeg@2cf008000 {
		compatible = "apple,t6031-jpeg", "apple,jpeg";
		reg = <0x2 0xcf008000 0x0 0x8000>;
		interrupt-parent = <&aic>;
		interrupts = <AIC_IRQ 0 1287 IRQ_TYPE_LEVEL_HIGH>;
		power-domains = <&ps_jpg>;
		iommus = <&dart_jpeg1 0>;
		status = "okay";
	};

	ave0: video-encoder@285100000 {
		compatible = "apple,t6031-ave", "apple,ave";
		reg = <0x2 0x85100000 0x0 0x45c000>,
		      <0x2 0x85800000 0x0 0x800000>,
		      <0x2 0x85050000 0x0 0x4000>,
		      <0x2 0x92800430 0x0 0x20c>,
		      <0x2 0x84000000 0x0 0x1000000>;
		interrupt-parent = <&aic>;
		interrupts = <AIC_IRQ 0 1207 IRQ_TYPE_LEVEL_HIGH>,
		             <AIC_IRQ 0 1201 IRQ_TYPE_LEVEL_HIGH>,
		             <AIC_IRQ 0 1200 IRQ_TYPE_LEVEL_HIGH>,
		             <AIC_IRQ 0 1203 IRQ_TYPE_LEVEL_HIGH>,
		             <AIC_IRQ 0 1202 IRQ_TYPE_LEVEL_HIGH>;
		power-domains = <&ps_venc0_sys>, <&ps_venc0_pipe4>, <&ps_venc0_pipe5>, <&ps_venc0_me0>, <&ps_venc0_me1>, <&ps_venc0_dma>;
		iommus = <&dart_ave00 0>, <&dart_ave01 0>;
		status = "disabled";
	};

	ave1: video-encoder@3c5100000 {
		compatible = "apple,t6031-ave", "apple,ave";
		reg = <0x3 0xc5100000 0x0 0x45c000>,
		      <0x3 0xc5800000 0x0 0x800000>,
		      <0x3 0xc5050000 0x0 0x4000>,
		      <0x2 0x92280510 0x0 0x7b14>,
		      <0x3 0xc4000000 0x0 0x1000000>;
		interrupt-parent = <&aic>;
		interrupts = <AIC_IRQ 0 1219 IRQ_TYPE_LEVEL_HIGH>,
		             <AIC_IRQ 0 1213 IRQ_TYPE_LEVEL_HIGH>,
		             <AIC_IRQ 0 1212 IRQ_TYPE_LEVEL_HIGH>,
		             <AIC_IRQ 0 1215 IRQ_TYPE_LEVEL_HIGH>,
		             <AIC_IRQ 0 1214 IRQ_TYPE_LEVEL_HIGH>;
		power-domains = <&ps_venc1_pipe4>, <&ps_venc1_pipe5>, <&ps_venc1_me0>, <&ps_venc1_me1>, <&ps_venc1_dma>;
		iommus = <&dart_ave10 0>, <&dart_ave11 0>;
		status = "disabled";
	};

};
